# CM55F register map
Registers are read-write, no defined reset value unless marked. A register's access mark holds for its fields unless they carry their own. Offsets are from the block's base; [hi:lo] are bit positions; {n}, {i} and the like mark numbered series.

## ICB — Implementation Control Block
Base 0xE000E004
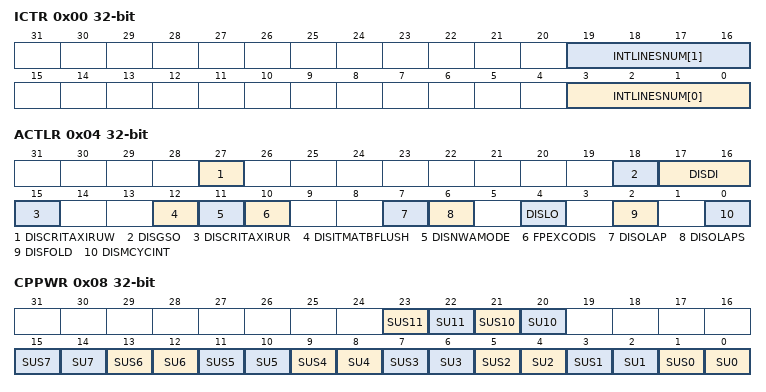
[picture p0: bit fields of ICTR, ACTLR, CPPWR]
0x00 ICTR ro — Interrupt Controller Type Register provides information about the interrupt controller
  [16n+3:16n] INTLINESNUM[{n}] (n=0..1) — The total number of interrupt lines supported by an implementation, defined in groups of 32
0x04 ACTLR — Auxiliary Control Register allow software to control the processor features and functionality
  [27] DISCRITAXIRUW — Disable-Critical-AXI-Read-Under-Write
    0=Normal operation; 1=AXI reads to Device memory and exclusive reads to shared memory are not initiated on the M-AXI read address channel until all outstanding writes on the M- AXI interface are complete
  [18] DISGSO — Disable gather and scatter optimization for contiguous accesses
  [17:16] DISDI — Disable dual-issue features
    0=Full dual-issue, if DISFOLD is set to 0; 1=Disable dual-issue of arithmetic instructions; 2=Disable lane swapping; 3=Disable dual-issue of arithmetic instructions and lane swapping
  [15] DISCRITAXIRUR — Disable critical AXI Read-Under-Read
    0=Normal operation; 1=AXI reads to Device memory and exclusive reads to shared memory are not initiated on the M-AXI read address channels if there are any outstanding reads on the M-AXI
  [12] DISITMATBFLUSH — Determines whether Instrumentation Trace Macrocell (ITM) or Data Watchpoint and Trace (DWT) ATB flush is disabled
    0=Normal operation; 1=ITM or DWT ATB flush is disabled
  [11] DISNWAMODE — Determines whether no write allocate mode is disabled
    0=Normal operation; 1=No write allocate mode is disabled
  [10] FPEXCODIS — Determines whether floating-point exception outputs are disabled
    0=Normal operation; 1=Floating-point exception outputs are disabled
  [7] DISOLAP — Disable overlapping of all instructions
  [6] DISOLAPS — Disable overlapping of scalar-only instructions
  [4] DISLO — Disable low overhead loops
    0=Low overhead loops enabled; 1=Low overhead loops disabled
  [2] DISFOLD — Determines whether dual-issue functionality is disabled
    0=Normal operation; 1=Dual-issue functionality is disabled
  [0] DISMCYCINT — Disables interruption of multi-cycle instructions
    0=Normal operation; 1=Disables interruption of multi-cycle instructions
0x08 CPPWR — Coprocessor Power Control Register specifies whether coprocessors are permitted to enter a non-retentive power state
  [23] SUS11 — If the value of this bit is not programmed to the same value as the SUS10 field, then the value is unknown.
  [22] SU11 — If the value of this bit is not programmed to the same value as the SU10 field, then the value is unknown.
  [21] SUS10 — This bit indicates and allows modification of whether the SU10 field can be modified from Non-secure state.
    0=The SU10 field is accessible from both Security states; 1=The SU10 field is only accessible from the Secure state
  [20] SU10 — This bit indicates and allows modification of whether the state associated with the floating-point and M-profile Vector Extension (MVE) functionality is permitted to become UNKNOWN.
    0=The floating-point and M-profile Vector Extension (MVE) state is not permitted to become unknown; 1=The floating-point and M-profile Vector Extension (MVE) state is permitted to become unknown
  [2n+1] SUS{n} (n=0..7) — This field indicates and allows modification of whether the SU{n} field can be modified from Non-secure state
    0=The SU{n} field is accessible from both Security states; 1=The SU{n} field is only accessible from the Secure state
  [2n] SU{n} (n=0..7) — This field indicates and allows modification of whether the state associated with coprocessor {n} is permitted to become unknown
    0=The coprocessor state is not permitted to become unknown; 1=The coprocessor state is permitted to become unknown
